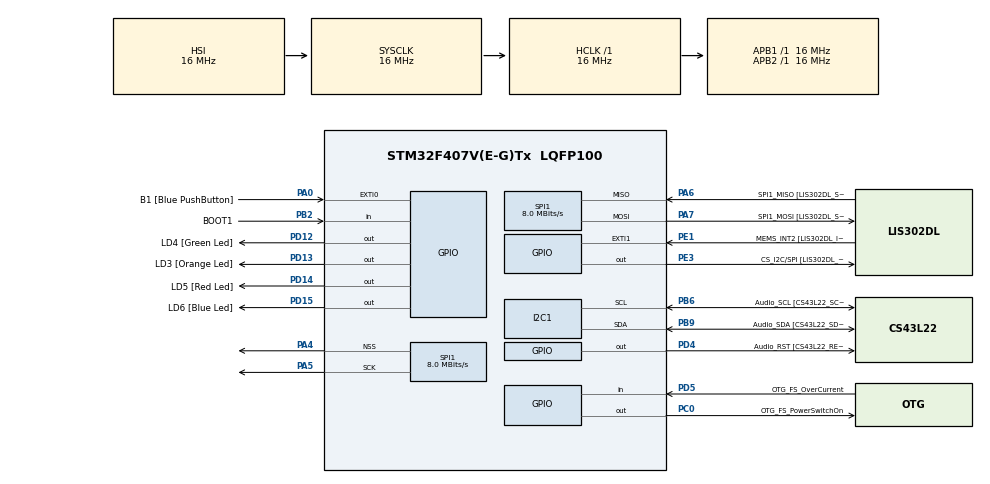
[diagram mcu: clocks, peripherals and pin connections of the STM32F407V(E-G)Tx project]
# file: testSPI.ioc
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Mcu.Family=STM32F4
Mcu.Name=STM32F407V(E-G)Tx
Mcu.Package=LQFP100
NVIC.PriorityGroup=NVIC_PRIORITYGROUP_0
PA0-WKUP.GPIO_Label=B1 [Blue PushButton]
PA0-WKUP.GPIO_ModeDefaultEXTI=GPIO_MODE_EVT_RISING
PA0-WKUP.GPIO_PuPd=GPIO_NOPULL
PA0-WKUP.Signal=GPXTI0
PA4.Mode=NSS_Signal_Hard_Output
PA4.Signal=SPI1_NSS
PA5.Mode=Full_Duplex_Master
PA5.Signal=SPI1_SCK
PA6.GPIO_Label=SPI1_MISO [LIS302DL_SDO]
PA6.GPIO_Mode=GPIO_MODE_AF_PP
PA6.GPIO_PuPd=GPIO_NOPULL
PA6.GPIO_Speed=GPIO_SPEED_FREQ_LOW
PA6.Mode=Full_Duplex_Master
PA6.Signal=SPI1_MISO
PA7.GPIO_Label=SPI1_MOSI [LIS302DL_SDA/SDI/SDO]
PA7.GPIO_Mode=GPIO_MODE_AF_PP
PA7.GPIO_PuPd=GPIO_NOPULL
PA7.GPIO_Speed=GPIO_SPEED_FREQ_LOW
PA7.Mode=Full_Duplex_Master
PA7.Signal=SPI1_MOSI
PB10.GPIO_Label=CLK_IN [MP45DT02_CLK]
PB10.GPIO_Mode=GPIO_MODE_AF_PP
PB10.GPIO_PuPd=GPIO_NOPULL
PB10.GPIO_Speed=GPIO_SPEED_FREQ_LOW
PB10.Signal=I2S2_CK
PB2.GPIO_Label=BOOT1
PB2.GPIO_Mode=GPIO_MODE_INPUT
PB2.GPIO_PuPd=GPIO_NOPULL
PB2.Signal=GPIO_Input
PB3.GPIO_Label=SWO
PB3.Signal=SYS_JTDO-SWO
PB6.GPIO_Label=Audio_SCL [CS43L22_SCL]
PB6.GPIO_Mode=GPIO_MODE_AF_OD
PB6.GPIO_Pu=GPIO_PULLUP
PB6.GPIO_PuPd=GPIO_NOPULL
PB6.GPIO_Speed=GPIO_SPEED_FREQ_LOW
PB6.Mode=I2C
PB6.Signal=I2C1_SCL
PB9.GPIO_Label=Audio_SDA [CS43L22_SDA]
PB9.GPIO_Mode=GPIO_MODE_AF_OD
PB9.GPIO_Pu=GPIO_PULLUP
PB9.GPIO_PuPd=GPIO_NOPULL
PB9.GPIO_Speed=GPIO_SPEED_FREQ_LOW
PB9.Mode=I2C
PB9.Signal=I2C1_SDA
PC0.GPIO_Label=OTG_FS_PowerSwitchOn
PC0.GPIO_PuPd=GPIO_NOPULL
PC0.GPIO_Speed=GPIO_SPEED_FREQ_LOW
PC0.PinState=GPIO_PIN_SET
PC0.Signal=GPIO_Output
PC3.GPIO_Label=PDM_OUT [MP45DT02_DOUT]
PC3.GPIO_Mode=GPIO_MODE_AF_PP
PC3.GPIO_PuPd=GPIO_NOPULL
PC3.GPIO_Speed=GPIO_SPEED_FREQ_LOW
PC3.Signal=I2S2_SD
PD12.GPIO_Label=LD4 [Green Led]
PD12.GPIO_PuPd=GPIO_NOPULL
PD12.GPIO_Speed=GPIO_SPEED_FREQ_LOW
PD12.Signal=GPIO_Output
PD13.GPIO_Label=LD3 [Orange Led]
PD13.GPIO_PuPd=GPIO_NOPULL
PD13.GPIO_Speed=GPIO_SPEED_FREQ_LOW
PD13.Signal=GPIO_Output
PD14.GPIO_Label=LD5 [Red Led]
PD14.GPIO_PuPd=GPIO_NOPULL
PD14.GPIO_Speed=GPIO_SPEED_FREQ_LOW
PD14.Signal=GPIO_Output
PD15.GPIO_Label=LD6 [Blue Led]
PD15.GPIO_PuPd=GPIO_NOPULL
PD15.GPIO_Speed=GPIO_SPEED_FREQ_LOW
PD15.Signal=GPIO_Output
PD4.GPIO_Label=Audio_RST [CS43L22_RESET]
PD4.GPIO_PuPd=GPIO_NOPULL
PD4.GPIO_Speed=GPIO_SPEED_FREQ_LOW
PD4.Signal=GPIO_Output
PD5.GPIO_Label=OTG_FS_OverCurrent
PD5.GPIO_Mode=GPIO_MODE_INPUT
PD5.GPIO_PuPd=GPIO_NOPULL
PD5.Signal=GPIO_Input
PE1.GPIO_Label=MEMS_INT2 [LIS302DL_INT2]
PE1.GPIO_ModeDefaultEXTI=GPIO_MODE_EVT_RISING
PE1.GPIO_PuPd=GPIO_NOPULL
PE1.Signal=GPXTI1
PE3.GPIO_Label=CS_I2C/SPI [LIS302DL_CS_I2C/SPI]
PE3.GPIO_PuPd=GPIO_NOPULL
PE3.GPIO_Speed=GPIO_SPEED_FREQ_LOW
PE3.Signal=GPIO_Output
ProjectManager.HeapSize=0x200
ProjectManager.StackSize=0x400
ProjectManager.TargetToolchain=STM32CubeIDE
RCC.48MHZClocksFreq_Value=50666666.666666664
RCC.AHBFreq_Value=16000000
RCC.APB1Freq_Value=16000000
RCC.APB1TimFreq_Value=16000000
RCC.APB2Freq_Value=16000000
RCC.APB2TimFreq_Value=16000000
RCC.CortexFreq_Value=16000000
RCC.HCLKFreq_Value=16000000
RCC.HSE_VALUE=8000000
RCC.HSI_VALUE=16000000
RCC.PLLM=9
RCC.PLLN=57
RCC.PLLP=RCC_PLLP_DIV8
RCC.PLLQ=2
RCC.SYSCLKFreq_VALUE=16000000
RCC.VCOOutputFreq_Value=101333333.33333333
SPI1.CalculateBaudRate=8.0 MBits/s
SPI1.Direction=SPI_DIRECTION_2LINES
SPI1.Mode=SPI_MODE_MASTER
SPI1.VirtualNSS=VM_NSSHARD
SPI1.VirtualType=VM_MASTER
board=STM32F407G-DISC1

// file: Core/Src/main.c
/* USER CODE BEGIN Header */
/**
  ******************************************************************************
  * @file           : main.c
  * @brief          : Main program body
  ******************************************************************************
  * @attention
  *
  * Copyright (c) 2025 STMicroelectronics.
  * All rights reserved.
  *
  * This software is licensed under terms that can be found in the LICENSE file
  * in the root directory of this software component.
  * If no LICENSE file comes with this software, it is provided AS-IS.
  *
  ******************************************************************************
  */
/* USER CODE END Header */
#include "main.h"

I2C_HandleTypeDef hi2c1;

SPI_HandleTypeDef hspi1;

void SystemClock_Config(void);
static void MX_GPIO_Init(void);
static void MX_I2C1_Init(void);
static void MX_SPI1_Init(void);

/* USER CODE BEGIN 0 */
uint8_t tx_data1[2] = {0x01, 0x02};
uint8_t rx_data1[2] = {0};
/* USER CODE END 0 */

int main(void)
{

  /* MCU Configuration--------------------------------------------------------*/

  /* Reset of all peripherals, Initializes the Flash interface and the Systick. */
  HAL_Init();

  /* Configure the system clock */
  SystemClock_Config();

  /* Initialize all configured peripherals */
  MX_GPIO_Init();
  MX_I2C1_Init();
  MX_SPI1_Init();
  /* USER CODE BEGIN 2 */
  HAL_SPI_TransmitReceive(&hspi1, tx_data1, rx_data1, 2, HAL_MAX_DELAY);
  /* USER CODE END 2 */

  /* Infinite loop */
  while (1)
  {

  }
}

void SystemClock_Config(void)
{
  RCC_OscInitTypeDef RCC_OscInitStruct = {0};
  RCC_ClkInitTypeDef RCC_ClkInitStruct = {0};

  /** Configure the main internal regulator output voltage
  */
  __HAL_RCC_PWR_CLK_ENABLE();
  __HAL_PWR_VOLTAGESCALING_CONFIG(PWR_REGULATOR_VOLTAGE_SCALE1);

  /** Initializes the RCC Oscillators according to the specified parameters
  * in the RCC_OscInitTypeDef structure.
  */
  RCC_OscInitStruct.OscillatorType = RCC_OSCILLATORTYPE_HSI;
  RCC_OscInitStruct.HSIState = RCC_HSI_ON;
  RCC_OscInitStruct.HSICalibrationValue = RCC_HSICALIBRATION_DEFAULT;
  RCC_OscInitStruct.PLL.PLLState = RCC_PLL_NONE;
  if (HAL_RCC_OscConfig(&RCC_OscInitStruct) != HAL_OK)
  {
    Error_Handler();
  }

  /** Initializes the CPU, AHB and APB buses clocks
  */
  RCC_ClkInitStruct.ClockType = RCC_CLOCKTYPE_HCLK|RCC_CLOCKTYPE_SYSCLK
                              |RCC_CLOCKTYPE_PCLK1|RCC_CLOCKTYPE_PCLK2;
  RCC_ClkInitStruct.SYSCLKSource = RCC_SYSCLKSOURCE_HSI;
  RCC_ClkInitStruct.AHBCLKDivider = RCC_SYSCLK_DIV1;
  RCC_ClkInitStruct.APB1CLKDivider = RCC_HCLK_DIV1;
  RCC_ClkInitStruct.APB2CLKDivider = RCC_HCLK_DIV1;

  if (HAL_RCC_ClockConfig(&RCC_ClkInitStruct, FLASH_LATENCY_0) != HAL_OK)
  {
    Error_Handler();
  }
}

static void MX_I2C1_Init(void)
{

  hi2c1.Instance = I2C1;
  hi2c1.Init.ClockSpeed = 100000;
  hi2c1.Init.DutyCycle = I2C_DUTYCYCLE_2;
  hi2c1.Init.OwnAddress1 = 0;
  hi2c1.Init.AddressingMode = I2C_ADDRESSINGMODE_7BIT;
  hi2c1.Init.DualAddressMode = I2C_DUALADDRESS_DISABLE;
  hi2c1.Init.OwnAddress2 = 0;
  hi2c1.Init.GeneralCallMode = I2C_GENERALCALL_DISABLE;
  hi2c1.Init.NoStretchMode = I2C_NOSTRETCH_DISABLE;
  if (HAL_I2C_Init(&hi2c1) != HAL_OK)
  {
    Error_Handler();
  }

}

static void MX_SPI1_Init(void)
{

  /* SPI1 parameter configuration*/
  hspi1.Instance = SPI1;
  hspi1.Init.Mode = SPI_MODE_MASTER;
  hspi1.Init.Direction = SPI_DIRECTION_2LINES;
  hspi1.Init.DataSize = SPI_DATASIZE_8BIT;
  hspi1.Init.CLKPolarity = SPI_POLARITY_LOW;
  hspi1.Init.CLKPhase = SPI_PHASE_1EDGE;
  hspi1.Init.NSS = SPI_NSS_HARD_OUTPUT;
  hspi1.Init.BaudRatePrescaler = SPI_BAUDRATEPRESCALER_2;
  hspi1.Init.FirstBit = SPI_FIRSTBIT_MSB;
  hspi1.Init.TIMode = SPI_TIMODE_DISABLE;
  hspi1.Init.CRCCalculation = SPI_CRCCALCULATION_DISABLE;
  hspi1.Init.CRCPolynomial = 10;
  if (HAL_SPI_Init(&hspi1) != HAL_OK)
  {
    Error_Handler();
  }

}

static void MX_GPIO_Init(void)
{
  GPIO_InitTypeDef GPIO_InitStruct = {0};

  /* GPIO Ports Clock Enable */
  __HAL_RCC_GPIOE_CLK_ENABLE();
  __HAL_RCC_GPIOC_CLK_ENABLE();
  __HAL_RCC_GPIOA_CLK_ENABLE();
  __HAL_RCC_GPIOB_CLK_ENABLE();
  __HAL_RCC_GPIOD_CLK_ENABLE();

  /*Configure GPIO pin Output Level */
  HAL_GPIO_WritePin(CS_I2C_SPI_GPIO_Port, CS_I2C_SPI_Pin, GPIO_PIN_RESET);

  /*Configure GPIO pin Output Level */
  HAL_GPIO_WritePin(OTG_FS_PowerSwitchOn_GPIO_Port, OTG_FS_PowerSwitchOn_Pin, GPIO_PIN_SET);

  /*Configure GPIO pin Output Level */
  HAL_GPIO_WritePin(GPIOD, LD4_Pin|LD3_Pin|LD5_Pin|LD6_Pin
                          |Audio_RST_Pin, GPIO_PIN_RESET);

  /*Configure GPIO pin : CS_I2C_SPI_Pin */
  GPIO_InitStruct.Pin = CS_I2C_SPI_Pin;
  GPIO_InitStruct.Mode = GPIO_MODE_OUTPUT_PP;
  GPIO_InitStruct.Pull = GPIO_NOPULL;
  GPIO_InitStruct.Speed = GPIO_SPEED_FREQ_LOW;
  HAL_GPIO_Init(CS_I2C_SPI_GPIO_Port, &GPIO_InitStruct);

  /*Configure GPIO pin : OTG_FS_PowerSwitchOn_Pin */
  GPIO_InitStruct.Pin = OTG_FS_PowerSwitchOn_Pin;
  GPIO_InitStruct.Mode = GPIO_MODE_OUTPUT_PP;
  GPIO_InitStruct.Pull = GPIO_NOPULL;
  GPIO_InitStruct.Speed = GPIO_SPEED_FREQ_LOW;
  HAL_GPIO_Init(OTG_FS_PowerSwitchOn_GPIO_Port, &GPIO_InitStruct);

  /*Configure GPIO pin : PDM_OUT_Pin */
  GPIO_InitStruct.Pin = PDM_OUT_Pin;
  GPIO_InitStruct.Mode = GPIO_MODE_AF_PP;
  GPIO_InitStruct.Pull = GPIO_NOPULL;
  GPIO_InitStruct.Speed = GPIO_SPEED_FREQ_LOW;
  GPIO_InitStruct.Alternate = GPIO_AF5_SPI2;
  HAL_GPIO_Init(PDM_OUT_GPIO_Port, &GPIO_InitStruct);

  /*Configure GPIO pin : B1_Pin */
  GPIO_InitStruct.Pin = B1_Pin;
  GPIO_InitStruct.Mode = GPIO_MODE_EVT_RISING;
  GPIO_InitStruct.Pull = GPIO_NOPULL;
  HAL_GPIO_Init(B1_GPIO_Port, &GPIO_InitStruct);

  /*Configure GPIO pin : BOOT1_Pin */
  GPIO_InitStruct.Pin = BOOT1_Pin;
  GPIO_InitStruct.Mode = GPIO_MODE_INPUT;
  GPIO_InitStruct.Pull = GPIO_NOPULL;
  HAL_GPIO_Init(BOOT1_GPIO_Port, &GPIO_InitStruct);

  /*Configure GPIO pin : CLK_IN_Pin */
  GPIO_InitStruct.Pin = CLK_IN_Pin;
  GPIO_InitStruct.Mode = GPIO_MODE_AF_PP;
  GPIO_InitStruct.Pull = GPIO_NOPULL;
  GPIO_InitStruct.Speed = GPIO_SPEED_FREQ_LOW;
  GPIO_InitStruct.Alternate = GPIO_AF5_SPI2;
  HAL_GPIO_Init(CLK_IN_GPIO_Port, &GPIO_InitStruct);

  /*Configure GPIO pins : LD4_Pin LD3_Pin LD5_Pin LD6_Pin
                           Audio_RST_Pin */
  GPIO_InitStruct.Pin = LD4_Pin|LD3_Pin|LD5_Pin|LD6_Pin
                          |Audio_RST_Pin;
  GPIO_InitStruct.Mode = GPIO_MODE_OUTPUT_PP;
  GPIO_InitStruct.Pull = GPIO_NOPULL;
  GPIO_InitStruct.Speed = GPIO_SPEED_FREQ_LOW;
  HAL_GPIO_Init(GPIOD, &GPIO_InitStruct);

  /*Configure GPIO pin : OTG_FS_OverCurrent_Pin */
  GPIO_InitStruct.Pin = OTG_FS_OverCurrent_Pin;
  GPIO_InitStruct.Mode = GPIO_MODE_INPUT;
  GPIO_InitStruct.Pull = GPIO_NOPULL;
  HAL_GPIO_Init(OTG_FS_OverCurrent_GPIO_Port, &GPIO_InitStruct);

  /*Configure GPIO pin : MEMS_INT2_Pin */
  GPIO_InitStruct.Pin = MEMS_INT2_Pin;
  GPIO_InitStruct.Mode = GPIO_MODE_EVT_RISING;
  GPIO_InitStruct.Pull = GPIO_NOPULL;
  HAL_GPIO_Init(MEMS_INT2_GPIO_Port, &GPIO_InitStruct);

}

void Error_Handler(void)
{
  __disable_irq();
  while (1)
  {
  }
}
